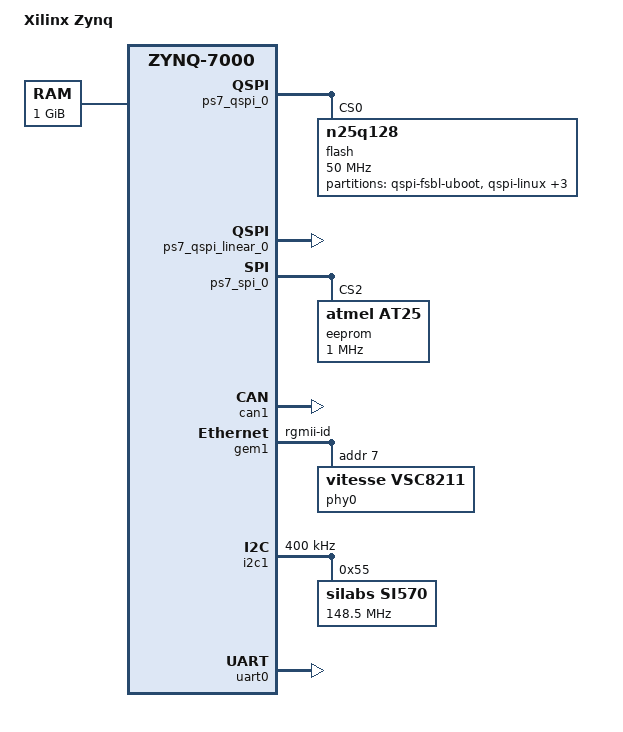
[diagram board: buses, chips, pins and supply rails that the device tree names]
/*
 * Device Tree Generator version: 1.1
 *
 * (C) Copyright 2007-2013 Xilinx, Inc.
 * (C) Copyright 2007-2013 Michal Simek
 * (C) Copyright 2007-2012 PetaLogix Qld Pty Ltd
 *
 * Michal SIMEK <monstr@monstr.eu>
 *
 * CAUTION: This file is automatically generated by libgen.
 * Version: Xilinx EDK 14.5 EDK_P.58f
 *
 */
/dts-v1/;
/include/ "zynq-7000.dtsi"

/ {
	compatible = "xlnx,zynq-zc770-xm013", "xlnx,zynq-7000";
	model = "Xilinx Zynq";

	aliases {
		ethernet0 = &gem1;
		i2c0 = &i2c1;
		serial0 = &uart0;
		spi0 = &ps7_spi_0;
		spi1 = &ps7_qspi_0;
	};

	chosen {
		bootargs = "console=ttyPS0,115200 root=/dev/ram rw earlyprintk";
		linux,stdout-path = "/amba/serial@e0000000";
	};

	memory@0 {
		device_type = "memory";
		reg = <0x0 0x40000000>;
	};

	amba {
		ps7_gpio_0: ps7-gpio@e000a000 {
			#gpio-cells = <2>;
			clocks = <&clkc 42>;
			compatible = "xlnx,zynq-gpio-1.0";
			emio-gpio-width = <64>;
			gpio-controller ;
			gpio-mask-high = <0xdc000>;
			gpio-mask-low = <0xfc00080>;
			interrupt-parent = <&intc>;
			interrupts = <0 20 4>;
			reg = <0xe000a000 0x1000>;
		} ;
		ps7_qspi_0: ps7-qspi@e000d000 {
			clock-names = "ref_clk", "pclk";
			clocks = <&clkc 10>, <&clkc 43>;
			compatible = "xlnx,zynq-qspi-1.0";
			interrupt-parent = <&intc>;
			interrupts = <0 19 4>;
			is-dual = <1>;
			num-cs = <1>;
			reg = <0xe000d000 0x1000>;
			xlnx,fb-clk = <0x1>;
			xlnx,qspi-mode = <0x2>;
			#address-cells = <1>;
			#size-cells = <0>;
			flash@0 {
				compatible = "n25q128";
				reg = <0x0>;
				spi-tx-bus-width = <1>;
				spi-rx-bus-width = <4>;
				spi-max-frequency = <50000000>;
				#address-cells = <1>;
				#size-cells = <1>;
				partition@qspi-fsbl-uboot {
					label = "qspi-fsbl-uboot";
					reg = <0x0 0x100000>;
				};
				partition@qspi-linux {
					label = "qspi-linux";
					reg = <0x100000 0x500000>;
				};
				partition@qspi-device-tree {
					label = "qspi-device-tree";
					reg = <0x600000 0x20000>;
				};
				partition@qspi-rootfs {
					label = "qspi-rootfs";
					reg = <0x620000 0x5E0000>;
				};
				partition@qspi-bitstream {
					label = "qspi-bitstream";
					reg = <0xC00000 0x400000>;
				};
			};

		} ;
		ps7_qspi_linear_0: ps7-qspi-linear@fc000000 {
			clock-names = "ref_clk", "aper_clk";
			clocks = <&clkc 10>, <&clkc 43>;
			compatible = "xlnx,ps7-qspi-linear-1.00.a";
			reg = <0xfc000000 0x2000000>;
		} ;
		ps7_scuwdt_0: ps7-scuwdt@f8f00620 {
			clocks = <&clkc 4>;
			compatible = "xlnx,ps7-scuwdt-1.00.a";
			device_type = "watchdog";
			interrupt-parent = <&intc>;
			interrupts = <1 14 0x301>;
			reg = <0xf8f00620 0xe0>;
		} ;
		ps7_spi_0: ps7-spi@e0006000 {
			clock-names = "ref_clk", "pclk";
			clocks = <&clkc 25>, <&clkc 34>;
			compatible = "cdns,spi-r1p6";
			interrupt-parent = <&intc>;
			interrupts = <0 26 4>;
			num-cs = <4>;
			is-decoded-cs = <0>;
			reg = <0xe0006000 0x1000>;
			#address-cells = <1>;
			#size-cells = <0>;
			eeprom: at25@0 {
				at25,byte-len = <8192>;
				at25,addr-mode = <2>;
				at25,page-size = <32>;

				compatible = "atmel,at25";
				reg = <2>;
				spi-max-frequency = <1000000>;
			};
		} ;
		ps7_wdt_0: ps7-wdt@f8005000 {
			clocks = <&clkc 45>;
			compatible = "xlnx,zynq-wdt-r1p2";
			device_type = "watchdog";
			interrupt-parent = <&intc>;
			interrupts = <0 9 1>;
			reg = <0xf8005000 0x1000>;
			reset = <0>;
			timeout-sec = <10>;
		} ;
	};
};

&can1 {
	status = "okay";
};

&gem1 {
	status = "okay";
	phy-mode = "rgmii-id";

	phy0: phy@7 {
		compatible = "vitesse,vsc8211";
		reg = <7>;
	};
};

&i2c1 {
	status = "okay";
	clock-frequency = <400000>;

	si570: clock-generator@55 {
		#clock-cells = <0>;
		compatible = "silabs,si570";
		temperature-stability = <50>;
		reg = <0x55>;
		factory-fout = <156250000>;
		clock-frequency = <148500000>;
	};
};

&uart0 {
	status = "okay";
};
